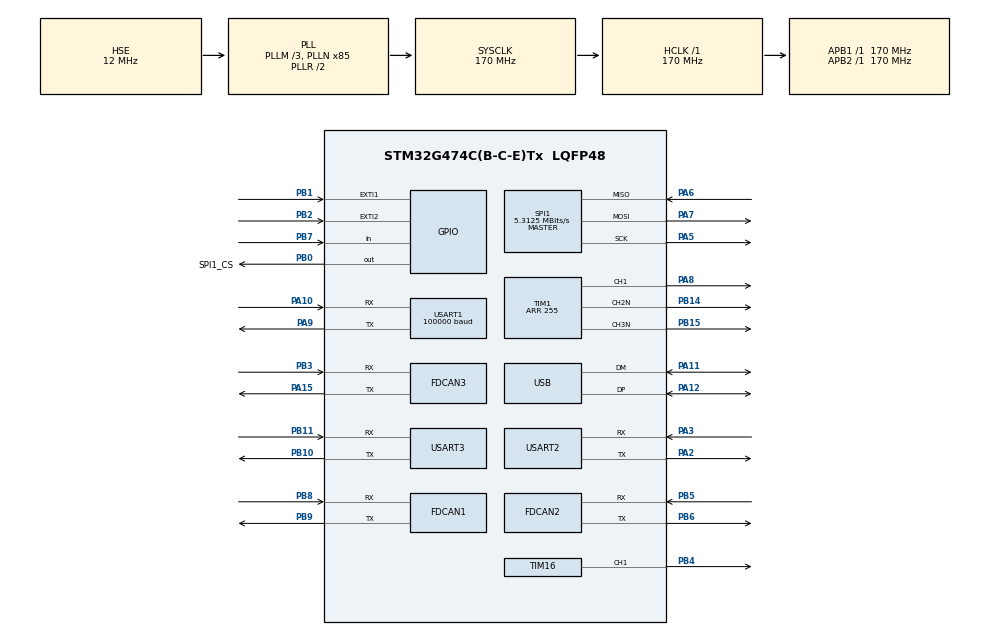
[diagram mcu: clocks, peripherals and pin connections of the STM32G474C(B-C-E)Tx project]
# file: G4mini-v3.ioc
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ADC1.Channel-0\#ChannelRegularConversion=ADC_CHANNEL_VBAT
ADC1.NbrOfConversionFlag=1
ADC1.OffsetNumber-0\#ChannelRegularConversion=ADC_OFFSET_NONE
ADC1.Rank-0\#ChannelRegularConversion=1
ADC1.SamplingTime-0\#ChannelRegularConversion=ADC_SAMPLETIME_2CYCLES_5
ADC1.master=1
Dma.Request0=USART1_RX
Dma.Request1=USART1_TX
Dma.Request2=USART2_RX
Dma.Request3=USART2_TX
Dma.Request4=USART3_RX
Dma.Request5=USART3_TX
Dma.Request6=SPI1_RX
Dma.Request7=SPI1_TX
Dma.SPI1_RX.6.Direction=DMA_PERIPH_TO_MEMORY
Dma.SPI1_RX.6.EventEnable=DISABLE
Dma.SPI1_RX.6.Instance=DMA1_Channel7
Dma.SPI1_RX.6.MemDataAlignment=DMA_MDATAALIGN_BYTE
Dma.SPI1_RX.6.MemInc=DMA_MINC_ENABLE
Dma.SPI1_RX.6.Mode=DMA_NORMAL
Dma.SPI1_RX.6.PeriphDataAlignment=DMA_PDATAALIGN_BYTE
Dma.SPI1_RX.6.PeriphInc=DMA_PINC_DISABLE
Dma.SPI1_RX.6.Polarity=HAL_DMAMUX_REQ_GEN_RISING
Dma.SPI1_RX.6.Priority=DMA_PRIORITY_LOW
Dma.SPI1_RX.6.RequestNumber=1
Dma.SPI1_RX.6.SignalID=NONE
Dma.SPI1_RX.6.SyncEnable=DISABLE
Dma.SPI1_RX.6.SyncPolarity=HAL_DMAMUX_SYNC_NO_EVENT
Dma.SPI1_RX.6.SyncRequestNumber=1
Dma.SPI1_RX.6.SyncSignalID=NONE
Dma.SPI1_TX.7.Direction=DMA_MEMORY_TO_PERIPH
Dma.SPI1_TX.7.EventEnable=DISABLE
Dma.SPI1_TX.7.Instance=DMA1_Channel8
Dma.SPI1_TX.7.MemDataAlignment=DMA_MDATAALIGN_BYTE
Dma.SPI1_TX.7.MemInc=DMA_MINC_ENABLE
Dma.SPI1_TX.7.Mode=DMA_NORMAL
Dma.SPI1_TX.7.PeriphDataAlignment=DMA_PDATAALIGN_BYTE
Dma.SPI1_TX.7.PeriphInc=DMA_PINC_DISABLE
Dma.SPI1_TX.7.Polarity=HAL_DMAMUX_REQ_GEN_RISING
Dma.SPI1_TX.7.Priority=DMA_PRIORITY_LOW
Dma.SPI1_TX.7.RequestNumber=1
Dma.SPI1_TX.7.SignalID=NONE
Dma.SPI1_TX.7.SyncEnable=DISABLE
Dma.SPI1_TX.7.SyncPolarity=HAL_DMAMUX_SYNC_NO_EVENT
Dma.SPI1_TX.7.SyncRequestNumber=1
Dma.SPI1_TX.7.SyncSignalID=NONE
Dma.USART1_RX.0.Direction=DMA_PERIPH_TO_MEMORY
Dma.USART1_RX.0.EventEnable=DISABLE
Dma.USART1_RX.0.Instance=DMA1_Channel1
Dma.USART1_RX.0.MemDataAlignment=DMA_MDATAALIGN_BYTE
Dma.USART1_RX.0.MemInc=DMA_MINC_ENABLE
Dma.USART1_RX.0.Mode=DMA_NORMAL
Dma.USART1_RX.0.PeriphDataAlignment=DMA_PDATAALIGN_BYTE
Dma.USART1_RX.0.PeriphInc=DMA_PINC_DISABLE
Dma.USART1_RX.0.Polarity=HAL_DMAMUX_REQ_GEN_RISING
Dma.USART1_RX.0.Priority=DMA_PRIORITY_MEDIUM
Dma.USART1_RX.0.RequestNumber=1
Dma.USART1_RX.0.SignalID=NONE
Dma.USART1_RX.0.SyncEnable=DISABLE
Dma.USART1_RX.0.SyncPolarity=HAL_DMAMUX_SYNC_NO_EVENT
Dma.USART1_RX.0.SyncRequestNumber=1
Dma.USART1_RX.0.SyncSignalID=NONE
Dma.USART1_TX.1.Direction=DMA_MEMORY_TO_PERIPH
Dma.USART1_TX.1.EventEnable=DISABLE
Dma.USART1_TX.1.Instance=DMA1_Channel2
Dma.USART1_TX.1.MemDataAlignment=DMA_MDATAALIGN_BYTE
Dma.USART1_TX.1.MemInc=DMA_MINC_ENABLE
Dma.USART1_TX.1.Mode=DMA_NORMAL
Dma.USART1_TX.1.PeriphDataAlignment=DMA_PDATAALIGN_BYTE
Dma.USART1_TX.1.PeriphInc=DMA_PINC_DISABLE
Dma.USART1_TX.1.Polarity=HAL_DMAMUX_REQ_GEN_RISING
Dma.USART1_TX.1.Priority=DMA_PRIORITY_LOW
Dma.USART1_TX.1.RequestNumber=1
Dma.USART1_TX.1.SignalID=NONE
Dma.USART1_TX.1.SyncEnable=DISABLE
Dma.USART1_TX.1.SyncPolarity=HAL_DMAMUX_SYNC_NO_EVENT
Dma.USART1_TX.1.SyncRequestNumber=1
Dma.USART1_TX.1.SyncSignalID=NONE
Dma.USART2_RX.2.Direction=DMA_PERIPH_TO_MEMORY
Dma.USART2_RX.2.EventEnable=DISABLE
Dma.USART2_RX.2.Instance=DMA1_Channel3
Dma.USART2_RX.2.MemDataAlignment=DMA_MDATAALIGN_BYTE
Dma.USART2_RX.2.MemInc=DMA_MINC_ENABLE
Dma.USART2_RX.2.Mode=DMA_NORMAL
Dma.USART2_RX.2.PeriphDataAlignment=DMA_PDATAALIGN_BYTE
Dma.USART2_RX.2.PeriphInc=DMA_PINC_DISABLE
Dma.USART2_RX.2.Polarity=HAL_DMAMUX_REQ_GEN_RISING
Dma.USART2_RX.2.Priority=DMA_PRIORITY_LOW
Dma.USART2_RX.2.RequestNumber=1
Dma.USART2_RX.2.SignalID=NONE
Dma.USART2_RX.2.SyncEnable=DISABLE
Dma.USART2_RX.2.SyncPolarity=HAL_DMAMUX_SYNC_NO_EVENT
Dma.USART2_RX.2.SyncRequestNumber=1
Dma.USART2_RX.2.SyncSignalID=NONE
Dma.USART2_TX.3.Direction=DMA_MEMORY_TO_PERIPH
Dma.USART2_TX.3.EventEnable=DISABLE
Dma.USART2_TX.3.Instance=DMA1_Channel4
Dma.USART2_TX.3.MemDataAlignment=DMA_MDATAALIGN_BYTE
Dma.USART2_TX.3.MemInc=DMA_MINC_ENABLE
Dma.USART2_TX.3.Mode=DMA_NORMAL
Dma.USART2_TX.3.PeriphDataAlignment=DMA_PDATAALIGN_BYTE
Dma.USART2_TX.3.PeriphInc=DMA_PINC_DISABLE
Dma.USART2_TX.3.Polarity=HAL_DMAMUX_REQ_GEN_RISING
Dma.USART2_TX.3.Priority=DMA_PRIORITY_LOW
Dma.USART2_TX.3.RequestNumber=1
Dma.USART2_TX.3.SignalID=NONE
Dma.USART2_TX.3.SyncEnable=DISABLE
Dma.USART2_TX.3.SyncPolarity=HAL_DMAMUX_SYNC_NO_EVENT
Dma.USART2_TX.3.SyncRequestNumber=1
Dma.USART2_TX.3.SyncSignalID=NONE
Dma.USART3_RX.4.Direction=DMA_PERIPH_TO_MEMORY
Dma.USART3_RX.4.EventEnable=DISABLE
Dma.USART3_RX.4.Instance=DMA1_Channel5
Dma.USART3_RX.4.MemDataAlignment=DMA_MDATAALIGN_BYTE
Dma.USART3_RX.4.MemInc=DMA_MINC_ENABLE
Dma.USART3_RX.4.Mode=DMA_NORMAL
Dma.USART3_RX.4.PeriphDataAlignment=DMA_PDATAALIGN_BYTE
Dma.USART3_RX.4.PeriphInc=DMA_PINC_DISABLE
Dma.USART3_RX.4.Polarity=HAL_DMAMUX_REQ_GEN_RISING
Dma.USART3_RX.4.Priority=DMA_PRIORITY_LOW
Dma.USART3_RX.4.RequestNumber=1
Dma.USART3_RX.4.SignalID=NONE
Dma.USART3_RX.4.SyncEnable=DISABLE
Dma.USART3_RX.4.SyncPolarity=HAL_DMAMUX_SYNC_NO_EVENT
Dma.USART3_RX.4.SyncRequestNumber=1
Dma.USART3_RX.4.SyncSignalID=NONE
Dma.USART3_TX.5.Direction=DMA_MEMORY_TO_PERIPH
Dma.USART3_TX.5.EventEnable=DISABLE
Dma.USART3_TX.5.Instance=DMA1_Channel6
Dma.USART3_TX.5.MemDataAlignment=DMA_MDATAALIGN_BYTE
Dma.USART3_TX.5.MemInc=DMA_MINC_ENABLE
Dma.USART3_TX.5.Mode=DMA_NORMAL
Dma.USART3_TX.5.PeriphDataAlignment=DMA_PDATAALIGN_BYTE
Dma.USART3_TX.5.PeriphInc=DMA_PINC_DISABLE
Dma.USART3_TX.5.Polarity=HAL_DMAMUX_REQ_GEN_RISING
Dma.USART3_TX.5.Priority=DMA_PRIORITY_LOW
Dma.USART3_TX.5.RequestNumber=1
Dma.USART3_TX.5.SignalID=NONE
Dma.USART3_TX.5.SyncEnable=DISABLE
Dma.USART3_TX.5.SyncPolarity=HAL_DMAMUX_SYNC_NO_EVENT
Dma.USART3_TX.5.SyncRequestNumber=1
Dma.USART3_TX.5.SyncSignalID=NONE
FDCAN1.CalculateBaudRateNominal=999999
FDCAN1.CalculateTimeBitNominal=1000
FDCAN1.CalculateTimeQuantumNominal=29.411764705882355
FDCAN1.NominalPrescaler=5
FDCAN1.NominalSyncJumpWidth=8
FDCAN1.NominalTimeSeg1=25
FDCAN1.NominalTimeSeg2=8
FDCAN1.StdFiltersNbr=28
FDCAN2.CalculateBaudRateNominal=999999
FDCAN2.CalculateTimeBitNominal=1000
FDCAN2.CalculateTimeQuantumNominal=29.411764705882355
FDCAN2.NominalPrescaler=5
FDCAN2.NominalSyncJumpWidth=8
FDCAN2.NominalTimeSeg1=25
FDCAN2.NominalTimeSeg2=8
FDCAN2.StdFiltersNbr=28
FDCAN3.CalculateBaudRateNominal=999999
FDCAN3.CalculateTimeBitNominal=1000
FDCAN3.CalculateTimeQuantumNominal=29.411764705882355
FDCAN3.NominalPrescaler=5
FDCAN3.NominalSyncJumpWidth=8
FDCAN3.NominalTimeSeg1=25
FDCAN3.NominalTimeSeg2=8
FDCAN3.StdFiltersNbr=28
FREERTOS.Tasks01=defaultTask,24,256,StartDefaultTask,Default,NULL,Dynamic,NULL,NULL
FREERTOS.configTOTAL_HEAP_SIZE=32767
Mcu.Family=STM32G4
Mcu.Name=STM32G474C(B-C-E)Tx
Mcu.Package=LQFP48
NVIC.DMA1_Channel1_IRQn=true\:5\:0\:false\:false\:true\:true\:false\:true\:true
NVIC.DMA1_Channel2_IRQn=true\:5\:0\:false\:false\:true\:true\:false\:true\:true
NVIC.DMA1_Channel3_IRQn=true\:5\:0\:false\:false\:true\:true\:false\:true\:true
NVIC.DMA1_Channel4_IRQn=true\:5\:0\:false\:false\:true\:true\:false\:true\:true
NVIC.DMA1_Channel5_IRQn=true\:5\:0\:false\:false\:true\:true\:false\:true\:true
NVIC.DMA1_Channel6_IRQn=true\:5\:0\:false\:false\:true\:true\:false\:true\:true
NVIC.DMA1_Channel7_IRQn=true\:5\:0\:false\:false\:true\:true\:false\:true\:true
NVIC.DMA1_Channel8_IRQn=true\:5\:0\:false\:false\:true\:true\:false\:true\:true
NVIC.FDCAN1_IT0_IRQn=true\:5\:0\:false\:false\:true\:true\:true\:true\:true
NVIC.FDCAN1_IT1_IRQn=true\:5\:0\:false\:false\:true\:true\:true\:true\:true
NVIC.FDCAN2_IT0_IRQn=true\:5\:0\:false\:false\:true\:true\:true\:true\:true
NVIC.FDCAN2_IT1_IRQn=true\:5\:0\:false\:false\:true\:true\:true\:true\:true
NVIC.FDCAN3_IT0_IRQn=true\:5\:0\:false\:false\:true\:true\:true\:true\:true
NVIC.FDCAN3_IT1_IRQn=true\:5\:0\:false\:false\:true\:true\:true\:true\:true
NVIC.PriorityGroup=NVIC_PRIORITYGROUP_4
NVIC.TIM7_DAC_IRQn=true\:15\:0\:false\:false\:true\:false\:false\:true\:true
NVIC.TimeBase=TIM7_DAC_IRQn
NVIC.TimeBaseIP=TIM7
NVIC.USART1_IRQn=true\:5\:0\:false\:false\:true\:true\:true\:true\:true
NVIC.USART2_IRQn=true\:5\:0\:false\:false\:true\:true\:true\:true\:true
NVIC.USART3_IRQn=true\:5\:0\:false\:false\:true\:true\:true\:true\:true
NVIC.USB_LP_IRQn=true\:5\:0\:false\:false\:true\:true\:false\:true\:true
PA10.GPIO_PuPd=GPIO_PULLUP
PA10.Mode=Asynchronous
PA10.Signal=USART1_RX
PA11.Mode=Device
PA11.Signal=USB_DM
PA12.Mode=Device
PA12.Signal=USB_DP
PA13.Mode=Serial_Wire
PA13.Signal=SYS_JTMS-SWDIO
PA14.Mode=Serial_Wire
PA14.Signal=SYS_JTCK-SWCLK
PA15.Mode=FDCAN_Activate
PA15.Signal=FDCAN3_TX
PA2.Mode=Asynchronous
PA2.Signal=USART2_TX
PA3.Mode=Asynchronous
PA3.Signal=USART2_RX
PA5.Mode=Full_Duplex_Master
PA5.Signal=SPI1_SCK
PA6.Mode=Full_Duplex_Master
PA6.Signal=SPI1_MISO
PA7.Mode=Full_Duplex_Master
PA7.Signal=SPI1_MOSI
PA8.Signal=S_TIM1_CH1
PA9.GPIO_PuPd=GPIO_PULLUP
PA9.Mode=Asynchronous
PA9.Signal=USART1_TX
PB0.GPIO_Label=SPI1_CS
PB0.Signal=GPIO_Output
PB1.Signal=GPXTI1
PB10.Mode=Asynchronous
PB10.Signal=USART3_TX
PB11.Mode=Asynchronous
PB11.Signal=USART3_RX
PB14.Mode=PWM Generation2 CH2N
PB14.Signal=TIM1_CH2N
PB15.Mode=PWM Generation3 CH3N
PB15.Signal=TIM1_CH3N
PB2.Signal=GPXTI2
PB3.Mode=FDCAN_Activate
PB3.Signal=FDCAN3_RX
PB4.Signal=S_TIM16_CH1
PB5.Mode=FDCAN_Activate
PB5.Signal=FDCAN2_RX
PB6.Mode=FDCAN_Activate
PB6.Signal=FDCAN2_TX
PB7.GPIO_PuPd=GPIO_PULLUP
PB7.Signal=GPIO_Input
PB8-BOOT0.Mode=FDCAN_Activate
PB8-BOOT0.Signal=FDCAN1_RX
PB9.Mode=FDCAN_Activate
PB9.Signal=FDCAN1_TX
PF0-OSC_IN.Mode=HSE-External-Oscillator
PF0-OSC_IN.Signal=RCC_OSC_IN
PF1-OSC_OUT.Mode=HSE-External-Oscillator
PF1-OSC_OUT.Signal=RCC_OSC_OUT
ProjectManager.HeapSize=0x200
ProjectManager.StackSize=0x400
ProjectManager.TargetToolchain=CMake
RCC.ADC12Freq_Value=170000000
RCC.ADC345Freq_Value=170000000
RCC.AHBFreq_Value=170000000
RCC.APB1Freq_Value=170000000
RCC.APB1TimFreq_Value=170000000
RCC.APB2Freq_Value=170000000
RCC.APB2TimFreq_Value=170000000
RCC.CK48CLockSelection=RCC_USBCLKSOURCE_HSI48
RCC.CortexFreq_Value=170000000
RCC.EXTERNAL_CLOCK_VALUE=12288000
RCC.HCLKFreq_Value=170000000
RCC.HSE_VALUE=12000000
RCC.HSI48_VALUE=48000000
RCC.HSI_VALUE=16000000
RCC.LSE_VALUE=32768
RCC.PLLM=RCC_PLLM_DIV3
RCC.PLLN=85
RCC.PLLQ=RCC_PLLQ_DIV8
RCC.PLLSourceVirtual=RCC_PLLSOURCE_HSE
RCC.SYSCLKFreq_VALUE=170000000
RCC.SYSCLKSource=RCC_SYSCLKSOURCE_PLLCLK
RCC.USBFreq_Value=48000000
RCC.VCOOutputFreq_Value=340000000
SH.S_TIM16_CH1.0=TIM16_CH1,PWM Generation1 CH1
SH.S_TIM1_CH1.0=TIM1_CH1,PWM Generation1 CH1
SPI1.BaudRatePrescaler=SPI_BAUDRATEPRESCALER_32
SPI1.CalculateBaudRate=5.3125 MBits/s
SPI1.DataSize=SPI_DATASIZE_8BIT
SPI1.Direction=SPI_DIRECTION_2LINES
SPI1.Mode=SPI_MODE_MASTER
SPI1.VirtualType=VM_MASTER
STMicroelectronics.X-CUBE-ALGOBUILD.1.5.0.LibraryCcDSPOoLibraryJjDSPOoLibrary=true
TIM1.AutoReloadPreload=TIM_AUTORELOAD_PRELOAD_ENABLE
TIM1.Channel-PWM\ Generation1\ CH1=TIM_CHANNEL_1
TIM1.Channel-PWM\ Generation2\ CH2N=TIM_CHANNEL_2
TIM1.Channel-PWM\ Generation3\ CH3N=TIM_CHANNEL_3
TIM1.OCMode_PWM-PWM\ Generation1\ CH1=TIM_OCMODE_PWM2
TIM1.OCMode_PWM-PWM\ Generation2\ CH2N=TIM_OCMODE_PWM2
TIM1.OCMode_PWM-PWM\ Generation3\ CH3N=TIM_OCMODE_PWM2
TIM1.PeriodNoDither=255
TIM16.Channel=TIM_CHANNEL_1
USART1.BaudRate=100000
USART1.Parity=PARITY_EVEN
USART1.RxPinLevelInvertParam=ADVFEATURE_RXINV_ENABLE
USART1.StopBits=STOPBITS_1
USART1.VirtualMode-Asynchronous=VM_ASYNC
USART1.WordLength=WORDLENGTH_9B
USART2.VirtualMode-Asynchronous=VM_ASYNC
USART3.VirtualMode-Asynchronous=VM_ASYNC
USB_DEVICE.CLASS_NAME_FS=CDC
USB_DEVICE.VirtualMode=Cdc
USB_DEVICE.VirtualModeFS=Cdc_FS
VP_ADC1_Vbat_Input.Mode=IN-Vbat
VP_FREERTOS_VS_CMSIS_V2.Mode=CMSIS_V2
VP_STMicroelectronics.X-CUBE-ALGOBUILD_VS_DSPOoLibraryJjLibrary_1.5.0_1.5.0.Mode=DSPOoLibraryJjLibrary
VP_SYS_VS_DBSignals.Mode=DisableDeadBatterySignals
VP_SYS_VS_tim7.Mode=TIM7
VP_TIM16_VS_ClockSourceINT.Mode=Enable_Timer
VP_TIM1_VS_ClockSourceINT.Mode=Internal
VP_TIM5_VS_ClockSourceINT.Mode=Internal
VP_USB_DEVICE_VS_USB_DEVICE_CDC_FS.Mode=CDC_FS
board=custom

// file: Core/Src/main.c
/* USER CODE BEGIN Header */
/**
  ******************************************************************************
  * @file           : main.c
  * @brief          : Main program body
  ******************************************************************************
  * @attention
  *
  * Copyright (c) 2026 STMicroelectronics.
  * All rights reserved.
  *
  * This software is licensed under terms that can be found in the LICENSE file
  * in the root directory of this software component.
  * If no LICENSE file comes with this software, it is provided AS-IS.
  *
  ******************************************************************************
  */
/* USER CODE END Header */
#include "main.h"
#include "cmsis_os.h"
#include "adc.h"
#include "dma.h"
#include "fdcan.h"
#include "spi.h"
#include "tim.h"
#include "usart.h"
#include "usb_device.h"
#include "gpio.h"

void SystemClock_Config(void);
void MX_FREERTOS_Init(void);

int main(void)
{

  /* MCU Configuration--------------------------------------------------------*/

  /* Reset of all peripherals, Initializes the Flash interface and the Systick. */
  HAL_Init();

  /* Configure the system clock */
  SystemClock_Config();

  /* Initialize all configured peripherals */
  MX_GPIO_Init();
  MX_DMA_Init();
  MX_ADC1_Init();
  MX_FDCAN1_Init();
  MX_FDCAN2_Init();
  MX_FDCAN3_Init();
  MX_SPI1_Init();
  MX_USART1_UART_Init();
  MX_USART2_UART_Init();
  MX_USART3_UART_Init();
  MX_TIM1_Init();
  MX_TIM5_Init();
  MX_TIM16_Init();

  /* Init scheduler */
  osKernelInitialize();  /* Call init function for freertos objects (in cmsis_os2.c) */
  MX_FREERTOS_Init();

  /* Start scheduler */
  osKernelStart();

  /* We should never get here as control is now taken by the scheduler */

  /* Infinite loop */
  while (1)
  {

  }
}

void SystemClock_Config(void)
{
  RCC_OscInitTypeDef RCC_OscInitStruct = {0};
  RCC_ClkInitTypeDef RCC_ClkInitStruct = {0};

  /** Configure the main internal regulator output voltage
  */
  HAL_PWREx_ControlVoltageScaling(PWR_REGULATOR_VOLTAGE_SCALE1_BOOST);

  /** Initializes the RCC Oscillators according to the specified parameters
  * in the RCC_OscInitTypeDef structure.
  */
  RCC_OscInitStruct.OscillatorType = RCC_OSCILLATORTYPE_HSI48|RCC_OSCILLATORTYPE_HSE;
  RCC_OscInitStruct.HSEState = RCC_HSE_ON;
  RCC_OscInitStruct.HSI48State = RCC_HSI48_ON;
  RCC_OscInitStruct.PLL.PLLState = RCC_PLL_ON;
  RCC_OscInitStruct.PLL.PLLSource = RCC_PLLSOURCE_HSE;
  RCC_OscInitStruct.PLL.PLLM = RCC_PLLM_DIV3;
  RCC_OscInitStruct.PLL.PLLN = 85;
  RCC_OscInitStruct.PLL.PLLP = RCC_PLLP_DIV2;
  RCC_OscInitStruct.PLL.PLLQ = RCC_PLLQ_DIV8;
  RCC_OscInitStruct.PLL.PLLR = RCC_PLLR_DIV2;
  if (HAL_RCC_OscConfig(&RCC_OscInitStruct) != HAL_OK)
  {
    Error_Handler();
  }

  /** Initializes the CPU, AHB and APB buses clocks
  */
  RCC_ClkInitStruct.ClockType = RCC_CLOCKTYPE_HCLK|RCC_CLOCKTYPE_SYSCLK
                              |RCC_CLOCKTYPE_PCLK1|RCC_CLOCKTYPE_PCLK2;
  RCC_ClkInitStruct.SYSCLKSource = RCC_SYSCLKSOURCE_PLLCLK;
  RCC_ClkInitStruct.AHBCLKDivider = RCC_SYSCLK_DIV1;
  RCC_ClkInitStruct.APB1CLKDivider = RCC_HCLK_DIV1;
  RCC_ClkInitStruct.APB2CLKDivider = RCC_HCLK_DIV1;

  if (HAL_RCC_ClockConfig(&RCC_ClkInitStruct, FLASH_LATENCY_4) != HAL_OK)
  {
    Error_Handler();
  }
}

void HAL_TIM_PeriodElapsedCallback(TIM_HandleTypeDef *htim)
{
  if (htim->Instance == TIM7)
  {
    HAL_IncTick();
  }
}

void Error_Handler(void)
{
  __disable_irq();
  while (1)
  {
  }
}

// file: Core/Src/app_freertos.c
/* USER CODE BEGIN Header */
/**
  ******************************************************************************
  * File Name          : app_freertos.c
  * Description        : Code for freertos applications
  ******************************************************************************
  * @attention
  *
  * Copyright (c) 2026 STMicroelectronics.
  * All rights reserved.
  *
  * This software is licensed under terms that can be found in the LICENSE file
  * in the root directory of this software component.
  * If no LICENSE file comes with this software, it is provided AS-IS.
  *
  ******************************************************************************
  */
/* USER CODE END Header */

#include "FreeRTOS.h"
#include "task.h"
#include "main.h"
#include "cmsis_os.h"

#include "usb_device.h"

/* USER CODE BEGIN Includes */
#include "ent_main.h"
/* USER CODE END Includes */

/* Definitions for defaultTask */
osThreadId_t defaultTaskHandle;
const osThreadAttr_t defaultTask_attributes = {
  .name = "defaultTask",
  .priority = (osPriority_t) osPriorityNormal,
  .stack_size = 256 * 4
};

void StartDefaultTask(void *argument);

void MX_FREERTOS_Init(void); /* (MISRA C 2004 rule 8.1) */

void MX_FREERTOS_Init(void) {

  /* Create the thread(s) */
  /* creation of defaultTask */
  defaultTaskHandle = osThreadNew(StartDefaultTask, NULL, &defaultTask_attributes);

}

void StartDefaultTask(void *argument)
{
  /* init code for USB_Device */
  MX_USB_Device_Init();
  /* USER CODE BEGIN StartDefaultTask */
        //用户入口: 初始化所有外设驱动并创建应用任务
        main_init();

        /* Infinite loop */
        for (;;)
        {

                osDelay(pdMS_TO_TICKS(1));
        }
  /* USER CODE END StartDefaultTask */
}
